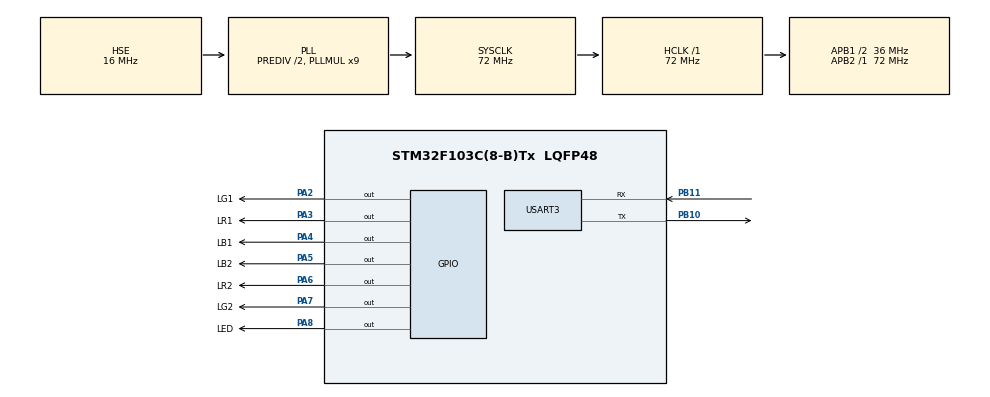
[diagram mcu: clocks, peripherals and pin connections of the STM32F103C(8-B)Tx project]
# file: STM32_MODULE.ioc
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Dma.Request0=TIM2_UP
Dma.Request1=TIM3_CH4/UP
Dma.TIM2_UP.0.Direction=DMA_MEMORY_TO_PERIPH
Dma.TIM2_UP.0.Instance=DMA1_Channel2
Dma.TIM2_UP.0.MemDataAlignment=DMA_MDATAALIGN_WORD
Dma.TIM2_UP.0.MemInc=DMA_MINC_ENABLE
Dma.TIM2_UP.0.Mode=DMA_CIRCULAR
Dma.TIM2_UP.0.PeriphDataAlignment=DMA_PDATAALIGN_WORD
Dma.TIM2_UP.0.PeriphInc=DMA_PINC_DISABLE
Dma.TIM2_UP.0.Priority=DMA_PRIORITY_LOW
Dma.TIM3_CH4/UP.1.Direction=DMA_MEMORY_TO_PERIPH
Dma.TIM3_CH4/UP.1.Instance=DMA1_Channel3
Dma.TIM3_CH4/UP.1.MemDataAlignment=DMA_MDATAALIGN_WORD
Dma.TIM3_CH4/UP.1.MemInc=DMA_MINC_ENABLE
Dma.TIM3_CH4/UP.1.Mode=DMA_CIRCULAR
Dma.TIM3_CH4/UP.1.PeriphDataAlignment=DMA_PDATAALIGN_WORD
Dma.TIM3_CH4/UP.1.PeriphInc=DMA_PINC_DISABLE
Dma.TIM3_CH4/UP.1.Priority=DMA_PRIORITY_LOW
Mcu.Family=STM32F1
Mcu.Name=STM32F103C(8-B)Tx
Mcu.Package=LQFP48
NVIC.DMA1_Channel2_IRQn=true\:0\:0\:false\:false\:true\:false\:true\:true
NVIC.DMA1_Channel3_IRQn=true\:0\:0\:false\:false\:true\:false\:true\:true
NVIC.PriorityGroup=NVIC_PRIORITYGROUP_4
NVIC.TIM2_IRQn=true\:0\:0\:false\:false\:true\:true\:true\:true
NVIC.TIM3_IRQn=true\:0\:0\:false\:false\:true\:true\:true\:true
NVIC.USART3_IRQn=true\:0\:0\:false\:false\:true\:true\:true\:true
PA13.Mode=Trace_Asynchronous_SW
PA13.Signal=SYS_JTMS-SWDIO
PA14.Mode=Trace_Asynchronous_SW
PA14.Signal=SYS_JTCK-SWCLK
PA2.GPIO_Label=LG1
PA2.Signal=GPIO_Output
PA3.GPIO_Label=LR1
PA3.Signal=GPIO_Output
PA4.GPIO_Label=LB1
PA4.Signal=GPIO_Output
PA5.GPIO_Label=LB2
PA5.Signal=GPIO_Output
PA6.GPIO_Label=LR2
PA6.Signal=GPIO_Output
PA7.GPIO_Label=LG2
PA7.Signal=GPIO_Output
PA8.GPIO_Label=LED
PA8.Signal=GPIO_Output
PB10.Mode=Asynchronous
PB10.Signal=USART3_TX
PB11.Mode=Asynchronous
PB11.Signal=USART3_RX
PB3.Mode=Trace_Asynchronous_SW
PB3.Signal=SYS_JTDO-TRACESWO
PD0-OSC_IN.Mode=HSE-External-Oscillator
PD0-OSC_IN.Signal=RCC_OSC_IN
PD1-OSC_OUT.Mode=HSE-External-Oscillator
PD1-OSC_OUT.Signal=RCC_OSC_OUT
ProjectManager.HeapSize=0x200
ProjectManager.StackSize=0x400
ProjectManager.TargetToolchain=STM32CubeIDE
RCC.AHBFreq_Value=72000000
RCC.APB1CLKDivider=RCC_HCLK_DIV2
RCC.APB1Freq_Value=36000000
RCC.APB1TimFreq_Value=72000000
RCC.APB2Freq_Value=72000000
RCC.APB2TimFreq_Value=72000000
RCC.HCLKFreq_Value=72000000
RCC.HSEDivPLL=RCC_HSE_PREDIV_DIV2
RCC.HSE_VALUE=16000000
RCC.PLLMUL=RCC_PLL_MUL9
RCC.PLLSourceVirtual=RCC_PLLSOURCE_HSE
RCC.SYSCLKFreq_VALUE=72000000
RCC.SYSCLKSource=RCC_SYSCLKSOURCE_PLLCLK
RCC.USBFreq_Value=72000000
TIM2.Period=50-1
TIM2.Prescaler=1
TIM2.TIM_MasterOutputTrigger=TIM_TRGO_UPDATE
TIM3.Period=50-1
TIM3.Prescaler=1
TIM3.TIM_MasterOutputTrigger=TIM_TRGO_UPDATE
USART3.VirtualMode=VM_ASYNC
VP_TIM2_VS_ClockSourceINT.Mode=Internal
VP_TIM3_VS_ClockSourceINT.Mode=Internal
board=custom

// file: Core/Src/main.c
/* USER CODE BEGIN Header */
/**
  ******************************************************************************
  * @file           : main.c
  * @brief          : Main program body
  ******************************************************************************
  * @attention
  *
  * Copyright (c) 2023 STMicroelectronics.
  * All rights reserved.
  *
  * This software is licensed under terms that can be found in the LICENSE file
  * in the root directory of this software component.
  * If no LICENSE file comes with this software, it is provided AS-IS.
  *
  ******************************************************************************
  */
/* USER CODE END Header */
#include "main.h"

/* USER CODE BEGIN Includes */
#include <stdio.h>
#include "user.h"
/* USER CODE END Includes */

TIM_HandleTypeDef htim2;
TIM_HandleTypeDef htim3;
DMA_HandleTypeDef hdma_tim2_up;
DMA_HandleTypeDef hdma_tim3_ch4_up;

UART_HandleTypeDef huart3;

void SystemClock_Config(void);
static void MX_GPIO_Init(void);
static void MX_DMA_Init(void);
static void MX_TIM2_Init(void);
static void MX_TIM3_Init(void);
static void MX_USART3_UART_Init(void);

/* USER CODE BEGIN 0 */
int __io_putchar(int ch)
{
 // Write character to ITM ch.0
 ITM_SendChar(ch);
 return(ch);
}
/* USER CODE END 0 */

int main(void)
{

  /* MCU Configuration--------------------------------------------------------*/

  /* Reset of all peripherals, Initializes the Flash interface and the Systick. */
  HAL_Init();

  /* Configure the system clock */
  SystemClock_Config();

  /* Initialize all configured peripherals */
  MX_GPIO_Init();
  MX_DMA_Init();
  MX_TIM2_Init();
  MX_TIM3_Init();
  MX_USART3_UART_Init();
  /* USER CODE BEGIN 2 */
  init();
  /* USER CODE END 2 */

  /* Infinite loop */
  /* USER CODE BEGIN WHILE */
  while (1)
  {
	  run();
    /* USER CODE END WHILE */

  }
}

void SystemClock_Config(void)
{
  RCC_OscInitTypeDef RCC_OscInitStruct = {0};
  RCC_ClkInitTypeDef RCC_ClkInitStruct = {0};

  /** Initializes the RCC Oscillators according to the specified parameters
  * in the RCC_OscInitTypeDef structure.
  */
  RCC_OscInitStruct.OscillatorType = RCC_OSCILLATORTYPE_HSE;
  RCC_OscInitStruct.HSEState = RCC_HSE_ON;
  RCC_OscInitStruct.HSEPredivValue = RCC_HSE_PREDIV_DIV2;
  RCC_OscInitStruct.HSIState = RCC_HSI_ON;
  RCC_OscInitStruct.PLL.PLLState = RCC_PLL_ON;
  RCC_OscInitStruct.PLL.PLLSource = RCC_PLLSOURCE_HSE;
  RCC_OscInitStruct.PLL.PLLMUL = RCC_PLL_MUL9;
  if (HAL_RCC_OscConfig(&RCC_OscInitStruct) != HAL_OK)
  {
    Error_Handler();
  }

  /** Initializes the CPU, AHB and APB buses clocks
  */
  RCC_ClkInitStruct.ClockType = RCC_CLOCKTYPE_HCLK|RCC_CLOCKTYPE_SYSCLK
                              |RCC_CLOCKTYPE_PCLK1|RCC_CLOCKTYPE_PCLK2;
  RCC_ClkInitStruct.SYSCLKSource = RCC_SYSCLKSOURCE_PLLCLK;
  RCC_ClkInitStruct.AHBCLKDivider = RCC_SYSCLK_DIV1;
  RCC_ClkInitStruct.APB1CLKDivider = RCC_HCLK_DIV2;
  RCC_ClkInitStruct.APB2CLKDivider = RCC_HCLK_DIV1;

  if (HAL_RCC_ClockConfig(&RCC_ClkInitStruct, FLASH_LATENCY_2) != HAL_OK)
  {
    Error_Handler();
  }
}

static void MX_TIM2_Init(void)
{

  TIM_ClockConfigTypeDef sClockSourceConfig = {0};
  TIM_MasterConfigTypeDef sMasterConfig = {0};

  htim2.Instance = TIM2;
  htim2.Init.Prescaler = 1;
  htim2.Init.CounterMode = TIM_COUNTERMODE_UP;
  htim2.Init.Period = 50-1;
  htim2.Init.ClockDivision = TIM_CLOCKDIVISION_DIV1;
  htim2.Init.AutoReloadPreload = TIM_AUTORELOAD_PRELOAD_DISABLE;
  if (HAL_TIM_Base_Init(&htim2) != HAL_OK)
  {
    Error_Handler();
  }
  sClockSourceConfig.ClockSource = TIM_CLOCKSOURCE_INTERNAL;
  if (HAL_TIM_ConfigClockSource(&htim2, &sClockSourceConfig) != HAL_OK)
  {
    Error_Handler();
  }
  sMasterConfig.MasterOutputTrigger = TIM_TRGO_UPDATE;
  sMasterConfig.MasterSlaveMode = TIM_MASTERSLAVEMODE_DISABLE;
  if (HAL_TIMEx_MasterConfigSynchronization(&htim2, &sMasterConfig) != HAL_OK)
  {
    Error_Handler();
  }

}

static void MX_TIM3_Init(void)
{

  TIM_ClockConfigTypeDef sClockSourceConfig = {0};
  TIM_MasterConfigTypeDef sMasterConfig = {0};

  htim3.Instance = TIM3;
  htim3.Init.Prescaler = 1;
  htim3.Init.CounterMode = TIM_COUNTERMODE_UP;
  htim3.Init.Period = 50-1;
  htim3.Init.ClockDivision = TIM_CLOCKDIVISION_DIV1;
  htim3.Init.AutoReloadPreload = TIM_AUTORELOAD_PRELOAD_DISABLE;
  if (HAL_TIM_Base_Init(&htim3) != HAL_OK)
  {
    Error_Handler();
  }
  sClockSourceConfig.ClockSource = TIM_CLOCKSOURCE_INTERNAL;
  if (HAL_TIM_ConfigClockSource(&htim3, &sClockSourceConfig) != HAL_OK)
  {
    Error_Handler();
  }
  sMasterConfig.MasterOutputTrigger = TIM_TRGO_UPDATE;
  sMasterConfig.MasterSlaveMode = TIM_MASTERSLAVEMODE_DISABLE;
  if (HAL_TIMEx_MasterConfigSynchronization(&htim3, &sMasterConfig) != HAL_OK)
  {
    Error_Handler();
  }

}

static void MX_USART3_UART_Init(void)
{

  huart3.Instance = USART3;
  huart3.Init.BaudRate = 115200;
  huart3.Init.WordLength = UART_WORDLENGTH_8B;
  huart3.Init.StopBits = UART_STOPBITS_1;
  huart3.Init.Parity = UART_PARITY_NONE;
  huart3.Init.Mode = UART_MODE_TX_RX;
  huart3.Init.HwFlowCtl = UART_HWCONTROL_NONE;
  huart3.Init.OverSampling = UART_OVERSAMPLING_16;
  if (HAL_UART_Init(&huart3) != HAL_OK)
  {
    Error_Handler();
  }

}

static void MX_DMA_Init(void)
{

  /* DMA controller clock enable */
  __HAL_RCC_DMA1_CLK_ENABLE();

  /* DMA interrupt init */
  /* DMA1_Channel2_IRQn interrupt configuration */
  HAL_NVIC_SetPriority(DMA1_Channel2_IRQn, 0, 0);
  HAL_NVIC_EnableIRQ(DMA1_Channel2_IRQn);
  /* DMA1_Channel3_IRQn interrupt configuration */
  HAL_NVIC_SetPriority(DMA1_Channel3_IRQn, 0, 0);
  HAL_NVIC_EnableIRQ(DMA1_Channel3_IRQn);

}

static void MX_GPIO_Init(void)
{
  GPIO_InitTypeDef GPIO_InitStruct = {0};

  /* GPIO Ports Clock Enable */
  __HAL_RCC_GPIOD_CLK_ENABLE();
  __HAL_RCC_GPIOA_CLK_ENABLE();
  __HAL_RCC_GPIOB_CLK_ENABLE();

  /*Configure GPIO pin Output Level */
  HAL_GPIO_WritePin(GPIOA, LG1_Pin|LR1_Pin|LB1_Pin|LB2_Pin
                          |LR2_Pin|LG2_Pin|LED_Pin, GPIO_PIN_RESET);

  /*Configure GPIO pins : LG1_Pin LR1_Pin LB1_Pin LB2_Pin
                           LR2_Pin LG2_Pin LED_Pin */
  GPIO_InitStruct.Pin = LG1_Pin|LR1_Pin|LB1_Pin|LB2_Pin
                          |LR2_Pin|LG2_Pin|LED_Pin;
  GPIO_InitStruct.Mode = GPIO_MODE_OUTPUT_PP;
  GPIO_InitStruct.Pull = GPIO_NOPULL;
  GPIO_InitStruct.Speed = GPIO_SPEED_FREQ_LOW;
  HAL_GPIO_Init(GPIOA, &GPIO_InitStruct);

}

void Error_Handler(void)
{
  /* USER CODE BEGIN Error_Handler_Debug */
  /* User can add their own implementation to report the HAL error return state */
  __disable_irq();
  while (1)
  {
	  err();
  }
  /* USER CODE END Error_Handler_Debug */
}

#ifdef  USE_FULL_ASSERT
/**
  * @brief  Reports the name of the source file and the source line number
  *         where the assert_param error has occurred.
  * @param  file: pointer to the source file name
  * @param  line: assert_param error line source number
  * @retval None
  */
void assert_failed(uint8_t *file, uint32_t line)
{
  /* USER CODE BEGIN 6 */
  /* User can add their own implementation to report the file name and line number */
  printf("Wrong parameters value: file %s on line %ld\r\n", file, line);
  /* USER CODE END 6 */
}
#endif /* USE_FULL_ASSERT */
